# lpcmp_reva_me30 register map
Registers are access not given, no defined reset value unless marked. A register's access mark holds for its fields unless they carry their own. Offsets are from the block's base; lines under a group give offsets from that group; [hi:lo] are bit positions; {n}, {i} and the like mark numbered series; 'fields as' and 'values as' point back to an identical list; <NAME> marks a mode.

## Memory map
0x40088000 LPCMP size 0x400 — Low Power Comparator

## Interrupts
103 LPCMP — Low Power Comparato

## LPCMP — Low Power Comparator
Base 0x40088000
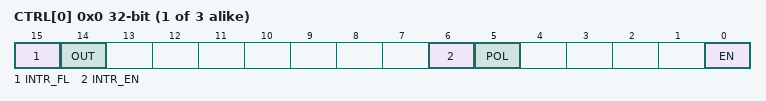
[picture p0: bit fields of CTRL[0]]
{0x0+4i} CTRL[{i}] (i=0..2) — Comparator Control Register.
  [15] INTR_FL — IRQ Flag
  [14] OUT — Raw Compartor Input.
  [6] INTR_EN — IRQ Enable.
  [5] POL — Polarity Select
  [0] EN — Comparator Enable.
